# ATUC128D3 device description
Architecture: AVR32_UC3; Family: AVR UC3
Registers are 32-bit, read-write, reset 0x0 unless marked. A register's access mark holds for its fields unless they carry their own. Offsets are from the block's base; [hi:lo] are bit positions; {n}, {i} and the like mark numbered series; 'fields as' and 'values as' point back to an identical list; <NAME> marks a mode.

## USART — Universal Synchronous Asynchronous Receiver Transmitter
Instances: USART0 0xffff3000, USART1 0xffff3400, USART2 0xffff3800
0x00 CR wo reset not defined — Control Register
  [21] LINWKUP <LIN_MODE> — Sends a wakeup signal on the LIN bus
  [20] LINABT <LIN_MODE> — Abort the current LIN transmission
  [19] RTSDIS <LIN_MODE> — Request to Send Disable
  [18] RTSEN <LIN_MODE> — Request to Send Enable
  [17] DTRDIS <LIN_MODE> — Data Terminal Ready Disable
  [16] DTREN <LIN_MODE> — Data Terminal Ready Enable
  [15] RETTO <LIN_MODE> — Rearm Time-out
  [14] RSTNACK <LIN_MODE> — Reset Non Acknowledge
  [13] RSTIT <LIN_MODE> — Reset Iterations
  [12] SENDA <LIN_MODE> — Send Address
  [11] STTTO <LIN_MODE> — Start Time-out
  [10] STPBRK <LIN_MODE> — Stop Break
  [9] STTBRK <LIN_MODE> — Start Break
  [8] RSTSTA <LIN_MODE> — Reset Status Bits
  [7] TXDIS <LIN_MODE> — Transmitter Disable
  [6] TXEN <LIN_MODE> — Transmitter Enable
  [5] RXDIS <LIN_MODE> — Receiver Disable
  [4] RXEN <LIN_MODE> — Receiver Enable
  [3] RSTTX <LIN_MODE> — Reset Transmitter
  [2] RSTRX <LIN_MODE> — Reset Receiver
  [19] RCS <SPI_MASTER_MODE> — Release SPI Chip Select
  [18] FCS <SPI_MASTER_MODE> — Force SPI Chip Select
  [17] DTRDIS <SPI_MASTER_MODE> — Data Terminal Ready Disable
  [16] DTREN <SPI_MASTER_MODE> — Data Terminal Ready Enable
  [15] RETTO <SPI_MASTER_MODE> — Rearm Time-out
  [14] RSTNACK <SPI_MASTER_MODE> — Reset Non Acknowledge
  [13] RSTIT <SPI_MASTER_MODE> — Reset Iterations
  [12] SENDA <SPI_MASTER_MODE> — Send Address
  [11] STTTO <SPI_MASTER_MODE> — Start Time-out
  [10] STPBRK <SPI_MASTER_MODE> — Stop Break
  [9] STTBRK <SPI_MASTER_MODE> — Start Break
  [8] RSTSTA <SPI_MASTER_MODE> — Reset Status Bits
  [7] TXDIS <SPI_MASTER_MODE> — Transmitter Disable
  [6] TXEN <SPI_MASTER_MODE> — Transmitter Enable
  [5] RXDIS <SPI_MASTER_MODE> — Receiver Disable
  [4] RXEN <SPI_MASTER_MODE> — Receiver Enable
  [3] RSTTX <SPI_MASTER_MODE> — Reset Transmitter
  [2] RSTRX <SPI_MASTER_MODE> — Reset Receiver
  [19] RTSDIS <USART_MODE> — Request to Send Disable
  [18] RTSEN <USART_MODE> — Request to Send Enable
  [17] DTRDIS <USART_MODE> — Data Terminal Ready Disable
  [16] DTREN <USART_MODE> — Data Terminal Ready Enable
  [15] RETTO <USART_MODE> — Rearm Time-out
  [14] RSTNACK <USART_MODE> — Reset Non Acknowledge
  [13] RSTIT <USART_MODE> — Reset Iterations
  [12] SENDA <USART_MODE> — Send Address
  [11] STTTO <USART_MODE> — Start Time-out
  [10] STPBRK <USART_MODE> — Stop Break
  [9] STTBRK <USART_MODE> — Start Break
  [8] RSTSTA <USART_MODE> — Reset Status Bits
  [7] TXDIS <USART_MODE> — Transmitter Disable
  [6] TXEN <USART_MODE> — Transmitter Enable
  [5] RXDIS <USART_MODE> — Receiver Disable
  [4] RXEN <USART_MODE> — Receiver Enable
  [3] RSTTX <USART_MODE> — Reset Transmitter
  [2] RSTRX <USART_MODE> — Reset Receiver
0x04 MR — Mode Register
  [28] FILTER <SPI_MODE> — Infrared Receive Line Filter
  [26:24] MAX_ITERATION <SPI_MODE> — Max interation
  [21] DSNACK <SPI_MODE> — Disable Successive NACK
  [20] INACK <SPI_MODE> — Inhibit Non Acknowledge
  [19] OVER <SPI_MODE> — Oversampling Mode
    0=X16; 1=X8
  [18] CLKO <SPI_MODE> — Clock Output Select
  [17] MODE9 <SPI_MODE> — 9-bit Character Length
  [16] CPOL <SPI_MODE> — SPI Clock Polarity
    0=ZERO; 1=ONE
  [15:14] CHMODE <SPI_MODE> — Channel Mode
    0=NORMAL; 1=ECHO; 2=LOCAL_LOOP; 3=REMOTE_LOOP
  [13:12] NBSTOP <SPI_MODE> — Number of Stop Bits
    0=1; 1=1_5; 2=2
  [11:9] PAR <SPI_MODE> — Parity Type
    0=EVEN; 1=ODD; 2=SPACE; 3=MARK; 4=NONE; 6=MULTI
  [8] CPHA <SPI_MODE> — SPI CLock Phase
  [7:6] CHRL <SPI_MODE> — Character Length.
    {v}={v+5} (v=0..3)
  [5:4] USCLKS <SPI_MODE> — Clock Selection
    0=MCK; 1=MCK_DIV; 3=SCK
  [3:0] MODE <SPI_MODE> — Usart Mode
    0=NORMAL; 1=RS485; 2=HARDWARE; 3=MODEM; 4=ISO7816_T0; 6=ISO7816_T1; 8=IRDA; 10=LIN_Master; 11=LIN_Slave; 14=SPI_Master; 15=SPI_Slave
  [31] ONEBIT <USART_MODE> — Start Frame Delimiter selector
  [30] MODSYNC <USART_MODE> — Manchester Synchronization Mode
  [29] MAN <USART_MODE> — Manchester Encoder/Decoder Enable
  [28] FILTER <USART_MODE> — Infrared Receive Line Filter
  [26:24] MAX_ITERATION <USART_MODE> — Max interation
  [22] VAR_SYNC <USART_MODE> — Variable synchronization of command/data sync Start Frame Delimiter
  [21] DSNACK <USART_MODE> — Disable Successive NACK
  [20] INACK <USART_MODE> — Inhibit Non Acknowledge
  [19] OVER <USART_MODE> — Oversampling Mode
    0=X16; 1=X8
  [18] CLKO <USART_MODE> — Clock Output Select
  [17] MODE9 <USART_MODE> — 9-bit Character Length
  [16] MSBF <USART_MODE> — Bit Order
    0=LSBF; 1=MSBF
  [15:14] CHMODE <USART_MODE> — Channel Mode
    0=NORMAL; 1=ECHO; 2=LOCAL_LOOP; 3=REMOTE_LOOP
  [13:12] NBSTOP <USART_MODE> — Number of Stop Bits
    0=1; 1=1_5; 2=2
  [11:9] PAR <USART_MODE> — Parity Type
    0=EVEN; 1=ODD; 2=SPACE; 3=MARK; 4=NONE; 6=MULTI
  [8] SYNC <USART_MODE> — Synchronous Mode Select
  [7:6] CHRL <USART_MODE> — Character Length.
    {v}={v+5} (v=0..3)
  [5:4] USCLKS <USART_MODE> — Clock Selection
    0=MCK; 1=MCK_DIV; 3=SCK
  [3:0] MODE <USART_MODE> — Usart Mode
    values as MODE<SPI_MODE>
0x08 IER wo — Interrupt Enable Register
  [29] LINSNRE <LIN_MODE> — LIN Slave Not Responding Error Interrupt Enable
  [28] LINCE <LIN_MODE> — LIN Checksum Error Interrupt Enable
  [27] LINIPE <LIN_MODE> — LIN Identifier Parity Interrupt Enable
  [26] LINISFE <LIN_MODE> — LIN Inconsistent Synch Field Error Interrupt Enable
  [25] LINBE <LIN_MODE> — LIN Bus Error Interrupt Enable
  [19] CTSIC <LIN_MODE> — Clear to Send Input Change Interrupt Enable
  [18] DCDIC <LIN_MODE> — Data Carrier Detect Input Change Interrupt Enable
  [17] DSRIC <LIN_MODE> — Data Set Ready Input Change Enable
  [16] RIIC <LIN_MODE> — Ring Indicator Input Change Enable
  [15] LINTC <LIN_MODE> — LIN Transfer Conpleted Interrupt Enable
  [14] LINID <LIN_MODE> — LIN Identifier Sent or LIN Identifier Received Interrupt Enable
  [13] NACK <LIN_MODE> — Non Acknowledge or LIN Break Sent or LIN Break Received Interrupt Enable
  [12] RXBUFF <LIN_MODE> — Buffer Full Interrupt Enable
  [11] TXBUFE <LIN_MODE> — Buffer Empty Interrupt Enable
  [10] ITER <LIN_MODE> — Iteration Interrupt Enable
  [9] TXEMPTY <LIN_MODE> — Transmitter Empty Interrupt Enable
  [8] TIMEOUT <LIN_MODE> — Time-out Interrupt Enable
  [7] PARE <LIN_MODE> — Parity Error Interrupt Enable
  [6] FRAME <LIN_MODE> — Framing Error Interrupt Enable
  [5] OVRE <LIN_MODE> — Overrun Error Interrupt Enable
  [4] ENDTX <LIN_MODE> — End of Transmit Interrupt Enable
  [3] ENDRX <LIN_MODE> — End of Receive Transfer Interrupt Enable
  [2] RXBRK <LIN_MODE> — Receiver Break Interrupt Enable
  [1] TXRDY <LIN_MODE> — Transmitter Ready Interrupt Enable
  [0] RXRDY <LIN_MODE> — Receiver Ready Interrupt Enable
  [19] CTSIC <SPI_SLAVE_MODE> — Clear to Send Input Change Interrupt Enable
  [18] DCDIC <SPI_SLAVE_MODE> — Data Carrier Detect Input Change Interrupt Enable
  [17] DSRIC <SPI_SLAVE_MODE> — Data Set Ready Input Change Enable
  [16] RIIC <SPI_SLAVE_MODE> — Ring Indicator Input Change Enable
  [13] NACK <SPI_SLAVE_MODE> — Non Acknowledge Interrupt Enable
  [12] RXBUFF <SPI_SLAVE_MODE> — Buffer Full Interrupt Enable
  [11] TXBUFE <SPI_SLAVE_MODE> — Buffer Empty Interrupt Enable
  [10] UNRE <SPI_SLAVE_MODE> — SPI Underrun Error Interrupt Enable
  [9] TXEMPTY <SPI_SLAVE_MODE> — Transmitter Empty Interrupt Enable
  [8] TIMEOUT <SPI_SLAVE_MODE> — Time-out Interrupt Enable
  [7] PARE <SPI_SLAVE_MODE> — Parity Error Interrupt Enable
  [6] FRAME <SPI_SLAVE_MODE> — Framing Error Interrupt Enable
  [5] OVRE <SPI_SLAVE_MODE> — Overrun Error Interrupt Enable
  [4] ENDTX <SPI_SLAVE_MODE> — End of Transmit Interrupt Enable
  [3] ENDRX <SPI_SLAVE_MODE> — End of Receive Transfer Interrupt Enable
  [2] RXBRK <SPI_SLAVE_MODE> — Receiver Break Interrupt Enable
  [1] TXRDY <SPI_SLAVE_MODE> — Transmitter Ready Interrupt Enable
  [0] RXRDY <SPI_SLAVE_MODE> — Receiver Ready Interrupt Enable
  [24] MANEA <USART_MODE> — Manchester Error Interrupt Enable
  [20] MANE <USART_MODE> — Manchester Error Interrupt Enable
  [19] CTSIC <USART_MODE> — Clear to Send Input Change Interrupt Enable
  [18] DCDIC <USART_MODE> — Data Carrier Detect Input Change Interrupt Enable
  [17] DSRIC <USART_MODE> — Data Set Ready Input Change Enable
  [16] RIIC <USART_MODE> — Ring Indicator Input Change Enable
  [13] NACK <USART_MODE> — Non Acknowledge Interrupt Enable
  [12] RXBUFF <USART_MODE> — Buffer Full Interrupt Enable
  [11] TXBUFE <USART_MODE> — Buffer Empty Interrupt Enable
  [10] ITER <USART_MODE> — Iteration Interrupt Enable
  [9] TXEMPTY <USART_MODE> — Transmitter Empty Interrupt Enable
  [8] TIMEOUT <USART_MODE> — Time-out Interrupt Enable
  [7] PARE <USART_MODE> — Parity Error Interrupt Enable
  [6] FRAME <USART_MODE> — Framing Error Interrupt Enable
  [5] OVRE <USART_MODE> — Overrun Error Interrupt Enable
  [4] ENDTX <USART_MODE> — End of Transmit Interrupt Enable
  [3] ENDRX <USART_MODE> — End of Receive Transfer Interrupt Enable
  [2] RXBRK <USART_MODE> — Receiver Break Interrupt Enable
  [1] TXRDY <USART_MODE> — Transmitter Ready Interrupt Enable
  [0] RXRDY <USART_MODE> — Receiver Ready Interrupt Enable
0x0C IDR wo — Interrupt Disable Register
  [29] LINSNRE <LIN_MODE> — LIN Slave Not Responding Error Interrupt Disable
  [28] LINCE <LIN_MODE> — LIN Checksum Error Interrupt Disable
  [27] LINIPE <LIN_MODE> — LIN Identifier Parity Interrupt Disable
  [26] LINISFE <LIN_MODE> — LIN Inconsistent Synch Field Error Interrupt Disable
  [25] LINBE <LIN_MODE> — LIN Bus Error Interrupt Disable
  [19] CTSIC <LIN_MODE> — Clear to Send Input Change Interrupt Disable
  [18] DCDIC <LIN_MODE> — Data Carrier Detect Input Change Interrupt Disable
  [17] DSRIC <LIN_MODE> — Data Set Ready Input Change Disable
  [16] RIIC <LIN_MODE> — Ring Indicator Input Change Disable
  [15] LINTC <LIN_MODE> — LIN Transfer Conpleted Interrupt Disable
  [14] LINID <LIN_MODE> — LIN Identifier Sent or LIN Identifier Received Interrupt Disable
  [13] NACK <LIN_MODE> — Non Acknowledge or LIN Break Sent or LIN Break Received Interrupt Disable
  [12] RXBUFF <LIN_MODE> — Buffer Full Interrupt Disable
  [11] TXBUFE <LIN_MODE> — Buffer Empty Interrupt Disable
  [10] ITER <LIN_MODE> — Iteration Interrupt Disable
  [9] TXEMPTY <LIN_MODE> — Transmitter Empty Interrupt Disable
  [8] TIMEOUT <LIN_MODE> — Time-out Interrupt Disable
  [7] PARE <LIN_MODE> — Parity Error Interrupt Disable
  [6] FRAME <LIN_MODE> — Framing Error Interrupt Disable
  [5] OVRE <LIN_MODE> — Overrun Error Interrupt Disable
  [4] ENDTX <LIN_MODE> — End of Transmit Interrupt Disable
  [3] ENDRX <LIN_MODE> — End of Receive Transfer Interrupt Disable
  [2] RXBRK <LIN_MODE> — Receiver Break Interrupt Disable
  [1] TXRDY <LIN_MODE> — Transmitter Ready Interrupt Disable
  [0] RXRDY <LIN_MODE> — Receiver Ready Interrupt Disable
  [19] CTSIC <SPI_SLAVE_MODE> — Clear to Send Input Change Interrupt Disable
  [18] DCDIC <SPI_SLAVE_MODE> — Data Carrier Detect Input Change Interrupt Disable
  [17] DSRIC <SPI_SLAVE_MODE> — Data Set Ready Input Change Disable
  [16] RIIC <SPI_SLAVE_MODE> — Ring Indicator Input Change Disable
  [13] NACK <SPI_SLAVE_MODE> — Non Acknowledge Interrupt Disable
  [12] RXBUFF <SPI_SLAVE_MODE> — Buffer Full Interrupt Disable
  [11] TXBUFE <SPI_SLAVE_MODE> — Buffer Empty Interrupt Disable
  [10] UNRE <SPI_SLAVE_MODE> — SPI Underrun Error Interrupt Disable
  [9] TXEMPTY <SPI_SLAVE_MODE> — Transmitter Empty Interrupt Disable
  [8] TIMEOUT <SPI_SLAVE_MODE> — Time-out Interrupt Disable
  [7] PARE <SPI_SLAVE_MODE> — Parity Error Interrupt Disable
  [6] FRAME <SPI_SLAVE_MODE> — Framing Error Interrupt Disable
  [5] OVRE <SPI_SLAVE_MODE> — Overrun Error Interrupt Disable
  [4] ENDTX <SPI_SLAVE_MODE> — End of Transmit Interrupt Disable
  [3] ENDRX <SPI_SLAVE_MODE> — End of Receive Transfer Interrupt Disable
  [2] RXBRK <SPI_SLAVE_MODE> — Receiver Break Interrupt Disable
  [1] TXRDY <SPI_SLAVE_MODE> — Transmitter Ready Interrupt Disable
  [0] RXRDY <SPI_SLAVE_MODE> — Receiver Ready Interrupt Disable
  [24] MANEA <USART_MODE> — Manchester Error Interrupt Disable
  [20] MANE <USART_MODE> — Manchester Error Interrupt Disable
  [19] CTSIC <USART_MODE> — Clear to Send Input Change Interrupt Disable
  [18] DCDIC <USART_MODE> — Data Carrier Detect Input Change Interrupt Disable
  [17] DSRIC <USART_MODE> — Data Set Ready Input Change Disable
  [16] RIIC <USART_MODE> — Ring Indicator Input Change Disable
  [13] NACK <USART_MODE> — Non Acknowledge Interrupt Disable
  [12] RXBUFF <USART_MODE> — Buffer Full Interrupt Disable
  [11] TXBUFE <USART_MODE> — Buffer Empty Interrupt Disable
  [10] ITER <USART_MODE> — Iteration Interrupt Disable
  [9] TXEMPTY <USART_MODE> — Transmitter Empty Interrupt Disable
  [8] TIMEOUT <USART_MODE> — Time-out Interrupt Disable
  [7] PARE <USART_MODE> — Parity Error Interrupt Disable
  [6] FRAME <USART_MODE> — Framing Error Interrupt Disable
  [5] OVRE <USART_MODE> — Overrun Error Interrupt Disable
  [4] ENDTX <USART_MODE> — End of Transmit Interrupt Disable
  [3] ENDRX <USART_MODE> — End of Receive Transfer Interrupt Disable
  [2] RXBRK <USART_MODE> — Receiver Break Interrupt Disable
  [1] TXRDY <USART_MODE> — Transmitter Ready Interrupt Disable
  [0] RXRDY <USART_MODE> — Receiver Ready Interrupt Disable
0x10 IMR ro — Interrupt Mask Register
  [29] LINSNRE <LIN_MODE> — LIN Slave Not Responding Error Interrupt Mask
  [28] LINCE <LIN_MODE> — LIN Checksum Error Interrupt Mask
  [27] LINIPE <LIN_MODE> — LIN Identifier Parity Interrupt Mask
  [26] LINISFE <LIN_MODE> — LIN Inconsistent Synch Field Error Interrupt Mask
  [25] LINBE <LIN_MODE> — LIN Bus Error Interrupt Mask
  [19] CTSIC <LIN_MODE> — Clear to Send Input Change Interrupt Mask
  [18] DCDIC <LIN_MODE> — Data Carrier Detect Input Change Interrupt Mask
  [17] DSRIC <LIN_MODE> — Data Set Ready Input Change Mask
  [16] RIIC <LIN_MODE> — Ring Indicator Input Change Mask
  [15] LINTC <LIN_MODE> — LIN Transfer Conpleted Interrupt Mask
  [14] LINID <LIN_MODE> — LIN Identifier Sent or LIN Received Interrupt Mask
  [13] NACK <LIN_MODE> — Non Acknowledge or LIN Break Sent or LIN Break Received Interrupt Mask
  [12] RXBUFF <LIN_MODE> — Buffer Full Interrupt Mask
  [11] TXBUFE <LIN_MODE> — Buffer Empty Interrupt Mask
  [10] ITER <LIN_MODE> — Iteration Interrupt Mask
  [9] TXEMPTY <LIN_MODE> — TXEMPTY Interrupt Mask
  [8] TIMEOUT <LIN_MODE> — Time-out Interrupt Mask
  [7] PARE <LIN_MODE> — Parity Error Interrupt Mask
  [6] FRAME <LIN_MODE> — Framing Error Interrupt Mask
  [5] OVRE <LIN_MODE> — Overrun Error Interrupt Mask
  [4] ENDTX <LIN_MODE> — End of Transmit Interrupt Mask
  [3] ENDRX <LIN_MODE> — End of Receive Transfer Interrupt Mask
  [2] RXBRK <LIN_MODE> — Receiver Break Interrupt Mask
  [1] TXRDY <LIN_MODE> — TXRDY Interrupt Mask
  [0] RXRDY <LIN_MODE> — RXRDY Interrupt Mask
  [19] CTSIC <SPI_SLAVE_MODE> — Clear to Send Input Change Interrupt Mask
  [18] DCDIC <SPI_SLAVE_MODE> — Data Carrier Detect Input Change Interrupt Mask
  [17] DSRIC <SPI_SLAVE_MODE> — Data Set Ready Input Change Mask
  [16] RIIC <SPI_SLAVE_MODE> — Ring Indicator Input Change Mask
  [13] NACK <SPI_SLAVE_MODE> — Non Acknowledge Interrupt Mask
  [12] RXBUFF <SPI_SLAVE_MODE> — Buffer Full Interrupt Mask
  [11] TXBUFE <SPI_SLAVE_MODE> — Buffer Empty Interrupt Mask
  [10] UNRE <SPI_SLAVE_MODE> — SPI Underrun Error Interrupt Mask
  [9] TXEMPTY <SPI_SLAVE_MODE> — TXEMPTY Interrupt Mask
  [8] TIMEOUT <SPI_SLAVE_MODE> — Time-out Interrupt Mask
  [7] PARE <SPI_SLAVE_MODE> — Parity Error Interrupt Mask
  [6] FRAME <SPI_SLAVE_MODE> — Framing Error Interrupt Mask
  [5] OVRE <SPI_SLAVE_MODE> — Overrun Error Interrupt Mask
  [4] ENDTX <SPI_SLAVE_MODE> — End of Transmit Interrupt Mask
  [3] ENDRX <SPI_SLAVE_MODE> — End of Receive Transfer Interrupt Mask
  [2] RXBRK <SPI_SLAVE_MODE> — Receiver Break Interrupt Mask
  [1] TXRDY <SPI_SLAVE_MODE> — TXRDY Interrupt Mask
  [0] RXRDY <SPI_SLAVE_MODE> — RXRDY Interrupt Mask
  [24] MANEA <USART_MODE> — Manchester Error Interrupt Mask
  [20] MANE <USART_MODE>
  [19] CTSIC <USART_MODE> — Clear to Send Input Change Interrupt Mask
  [18] DCDIC <USART_MODE> — Data Carrier Detect Input Change Interrupt Mask
  [17] DSRIC <USART_MODE> — Data Set Ready Input Change Mask
  [16] RIIC <USART_MODE> — Ring Indicator Input Change Mask
  [13] NACK <USART_MODE> — Non Acknowledge Interrupt Mask
  [12] RXBUFF <USART_MODE> — Buffer Full Interrupt Mask
  [11] TXBUFE <USART_MODE> — Buffer Empty Interrupt Mask
  [10] ITER <USART_MODE> — Iteration Interrupt Mask
  [9] TXEMPTY <USART_MODE> — TXEMPTY Interrupt Mask
  [8] TIMEOUT <USART_MODE> — Time-out Interrupt Mask
  [7] PARE <USART_MODE> — Parity Error Interrupt Mask
  [6] FRAME <USART_MODE> — Framing Error Interrupt Mask
  [5] OVRE <USART_MODE> — Overrun Error Interrupt Mask
  [4] ENDTX <USART_MODE> — End of Transmit Interrupt Mask
  [3] ENDRX <USART_MODE> — End of Receive Transfer Interrupt Mask
  [2] RXBRK <USART_MODE> — Receiver Break Interrupt Mask
  [1] TXRDY <USART_MODE> — TXRDY Interrupt Mask
  [0] RXRDY <USART_MODE> — RXRDY Interrupt Mask
0x14 CSR ro — Channel Status Register
  [29] LINSNRE <LIN_MODE> — LIN Slave Not Responding Error
  [28] LINCE <LIN_MODE> — LIN Checksum Error
  [27] LINIPE <LIN_MODE> — LIN Identifier Parity Error
  [26] LINISFE <LIN_MODE> — LIN Inconsistent Synch Field Error
  [25] LINBE <LIN_MODE> — LIN Bit Error
  [23] CTS <LIN_MODE> — Image of CTS Input
  [22] DCD <LIN_MODE> — Image of DCD Input
  [21] DSR <LIN_MODE> — Image of DSR Input
  [20] RI <LIN_MODE> — Image of RI Input
  [19] CTSIC <LIN_MODE> — Clear to Send Input Change Flag
  [18] DCDIC <LIN_MODE> — Data Carrier Detect Input Change Flag
  [17] DSRIC <LIN_MODE> — Data Set Ready Input Change Flag
  [16] RIIC <LIN_MODE> — Ring Indicator Input Change Flag
  [15] LINTC <LIN_MODE> — LIN Transfer Conpleted
  [14] LINID <LIN_MODE> — LIN Identifier Sent or LIN Identifier Received
  [13] NACK <LIN_MODE> — Non Acknowledge or LIN Break Sent or LIN Break Received
  [12] RXBUFF <LIN_MODE> — Reception Buffer Full
  [11] TXBUFE <LIN_MODE> — Transmission Buffer Empty
  [10] ITER <LIN_MODE> — Max number of Repetitions Reached
  [9] TXEMPTY <LIN_MODE> — Transmitter Empty
  [8] TIMEOUT <LIN_MODE> — Receiver Time-out
  [7] PARE <LIN_MODE> — Parity Error
  [6] FRAME <LIN_MODE> — Framing Error
  [5] OVRE <LIN_MODE> — Overrun Error
  [4] ENDTX <LIN_MODE> — End of Transmitter Transfer
  [3] ENDRX <LIN_MODE> — End of Receiver Transfer
  [2] RXBRK <LIN_MODE> — Break Received/End of Break
  [1] TXRDY <LIN_MODE> — Transmitter Ready
  [0] RXRDY <LIN_MODE> — Receiver Ready
  [23] CTS <SPI_SLAVE_MODE> — Image of CTS Input
  [22] DCD <SPI_SLAVE_MODE> — Image of DCD Input
  [21] DSR <SPI_SLAVE_MODE> — Image of DSR Input
  [20] RI <SPI_SLAVE_MODE> — Image of RI Input
  [19] CTSIC <SPI_SLAVE_MODE> — Clear to Send Input Change Flag
  [18] DCDIC <SPI_SLAVE_MODE> — Data Carrier Detect Input Change Flag
  [17] DSRIC <SPI_SLAVE_MODE> — Data Set Ready Input Change Flag
  [16] RIIC <SPI_SLAVE_MODE> — Ring Indicator Input Change Flag
  [13] NACK <SPI_SLAVE_MODE> — Non Acknowledge
  [12] RXBUFF <SPI_SLAVE_MODE> — Reception Buffer Full
  [11] TXBUFE <SPI_SLAVE_MODE> — Transmission Buffer Empty
  [10] UNRE <SPI_SLAVE_MODE> — SPI Underrun Error
  [9] TXEMPTY <SPI_SLAVE_MODE> — Transmitter Empty
  [8] TIMEOUT <SPI_SLAVE_MODE> — Receiver Time-out
  [7] PARE <SPI_SLAVE_MODE> — Parity Error
  [6] FRAME <SPI_SLAVE_MODE> — Framing Error
  [5] OVRE <SPI_SLAVE_MODE> — Overrun Error
  [4] ENDTX <SPI_SLAVE_MODE> — End of Transmitter Transfer
  [3] ENDRX <SPI_SLAVE_MODE> — End of Receiver Transfer
  [2] RXBRK <SPI_SLAVE_MODE> — Break Received/End of Break
  [1] TXRDY <SPI_SLAVE_MODE> — Transmitter Ready
  [0] RXRDY <SPI_SLAVE_MODE> — Receiver Ready
  [24] MANERR <USART_MODE> — Manchester Error
  [23] CTS <USART_MODE> — Image of CTS Input
  [22] DCD <USART_MODE> — Image of DCD Input
  [21] DSR <USART_MODE> — Image of DSR Input
  [20] RI <USART_MODE> — Image of RI Input
  [19] CTSIC <USART_MODE> — Clear to Send Input Change Flag
  [18] DCDIC <USART_MODE> — Data Carrier Detect Input Change Flag
  [17] DSRIC <USART_MODE> — Data Set Ready Input Change Flag
  [16] RIIC <USART_MODE> — Ring Indicator Input Change Flag
  [13] NACK <USART_MODE> — Non Acknowledge
  [12] RXBUFF <USART_MODE> — Reception Buffer Full
  [11] TXBUFE <USART_MODE> — Transmission Buffer Empty
  [10] ITER <USART_MODE> — Max number of Repetitions Reached
  [9] TXEMPTY <USART_MODE> — Transmitter Empty
  [8] TIMEOUT <USART_MODE> — Receiver Time-out
  [7] PARE <USART_MODE> — Parity Error
  [6] FRAME <USART_MODE> — Framing Error
  [5] OVRE <USART_MODE> — Overrun Error
  [4] ENDTX <USART_MODE> — End of Transmitter Transfer
  [3] ENDRX <USART_MODE> — End of Receiver Transfer
  [2] RXBRK <USART_MODE> — Break Received/End of Break
  [1] TXRDY <USART_MODE> — Transmitter Ready
  [0] RXRDY <USART_MODE> — Receiver Ready
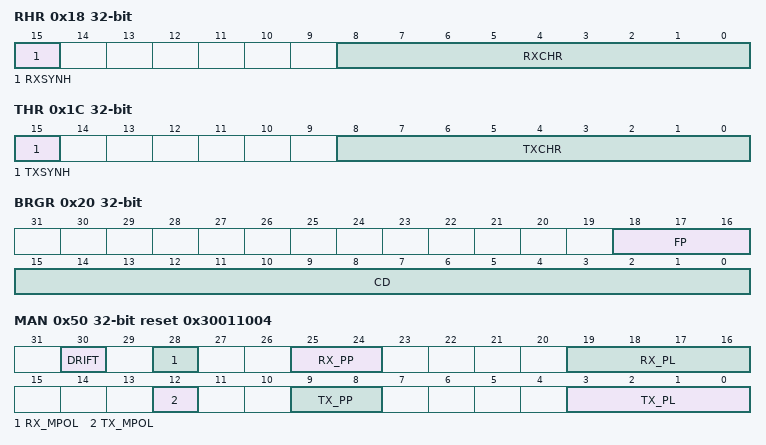
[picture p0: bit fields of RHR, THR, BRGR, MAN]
0x18 RHR ro — Receiver Holding Register
  [15] RXSYNH — Received Sync
  [8:0] RXCHR — Received Character
0x1C THR wo reset not defined — Transmitter Holding Register
  [15] TXSYNH — Sync Field to be transmitted
  [8:0] TXCHR — Character to be Transmitted
0x20 BRGR — Baud Rate Generator Register
  [18:16] FP — Fractional Part
  [15:0] CD — Clock Divisor
    0=DISABLE; 1=BYPASS
0x24 RTOR — Receiver Time-out Register
  [16:0] TO — Time-out Value
    0=DISABLE
0x28 TTGR — Transmitter Timeguard Register
  [7:0] TG — Timeguard Value
    0=DISABLE
0x40 FIDI reset 0x174 — FI DI Ratio Register
  [10:0] FI_DI_RATIO — FI Over DI Ratio Value
    0=DISABLE
0x44 NER ro — Number of Errors Register
  [7:0] NB_ERRORS — Error number during ISO7816 transfers
0x4C IFR — IrDA Filter Register
  [7:0] IRDA_FILTER
0x50 MAN reset 0x30011004 — Manchester Configuration Register
  [30] DRIFT — Drift compensation
  [28] RX_MPOL — Receiver Manchester Polarity
  [25:24] RX_PP — Receiver Preamble Pattern detected
  [19:16] RX_PL — Receiver Preamble Length
  [12] TX_MPOL — Transmitter Manchester Polarity
  [9:8] TX_PP — Transmitter Preamble Pattern
  [3:0] TX_PL — Transmitter Preamble Length
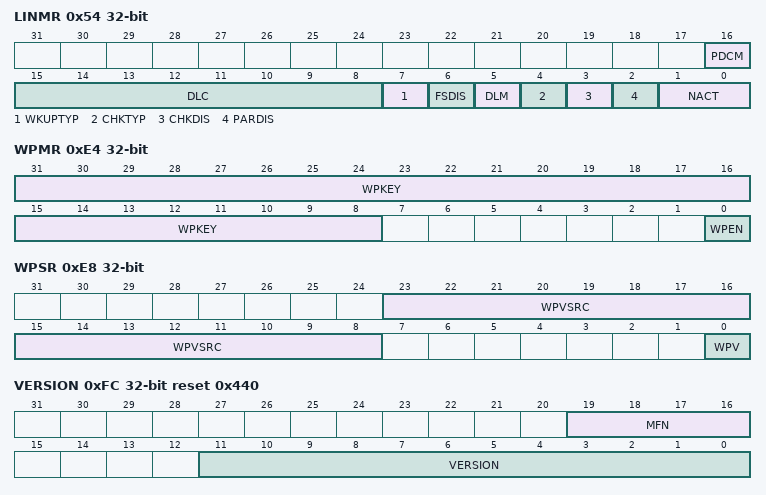
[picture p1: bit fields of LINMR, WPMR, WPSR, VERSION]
0x54 LINMR — LIN Mode Register
  [16] PDCM — PDC Mode
  [15:8] DLC — Data Length Control
  [7] WKUPTYP — Wakeup Signal Type
  [6] FSDIS — Frame Slot Mode Disable
  [5] DLM — Data Length Mode
  [4] CHKTYP — Checksum Type
  [3] CHKDIS — Checksum Disable
  [2] PARDIS — Parity Disable
  [1:0] NACT — LIN Node Action
    0=PUBLISH; 1=SUBSCRIBE; 2=IGNORE
0x58 LINIR — LIN Identifier Register
  [7:0] IDCHR — Identifier Character
0xE4 WPMR — Write Protect Mode Register
  [31:8] WPKEY — Write Protect Key
  [0] WPEN — Write Protect Enable
0xE8 WPSR ro — Write Protect Status Register
  [23:8] WPVSRC — Write Protect Violation Source
  [0] WPV — Write Protect Violation Status
0xFC VERSION ro reset 0x440
  [19:16] MFN, [11:0] VERSION
